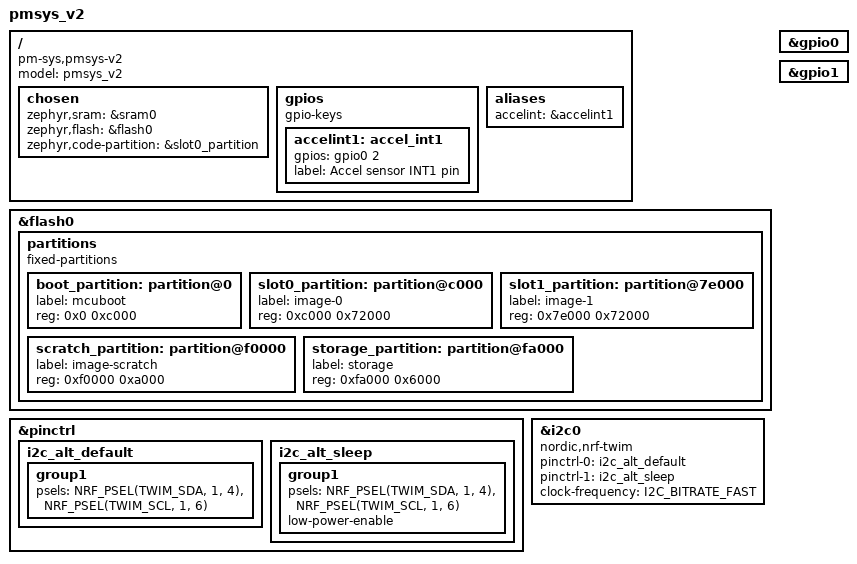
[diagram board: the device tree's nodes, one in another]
// Copyright (c) 2024 Nordic Semiconductor ASA
// SPDX-License-Identifier: Apache-2.0

/dts-v1/;
#include <nordic/nrf52840_qiaa.dtsi>

/ {
	model = "pmsys_v2";
	compatible = "pm-sys,pmsys-v2";

	chosen {
		zephyr,sram = &sram0;
		zephyr,flash = &flash0;
		zephyr,code-partition = &slot0_partition;
	};

	gpios {
		compatible = "gpio-keys";
		accelint1: accel_int1 {
			gpios = <&gpio0 2 (GPIO_PULL_DOWN | GPIO_ACTIVE_HIGH)>;
			label = "Accel sensor INT1 pin";
		};
	};

	aliases {
		accelint = &accelint1;
	};

};

&flash0 {
	partitions {
		compatible = "fixed-partitions";
		#address-cells = <1>;
		#size-cells = <1>;

		boot_partition: partition@0 {
			label = "mcuboot";
			reg = <0x0 0xc000>;
		};
		slot0_partition: partition@c000 {
			label = "image-0";
			reg = <0xc000 0x72000>;
		};
		slot1_partition: partition@7e000 {
			label = "image-1";
			reg = <0x7e000 0x72000>;
		};
		scratch_partition: partition@f0000 {
			label = "image-scratch";
			reg = <0xf0000 0xa000>;
		};
		storage_partition: partition@fa000 {
			label = "storage";
			reg = <0xfa000 0x6000>;
		};
	};
};

&gpio0 {
	status = "okay";
};

&gpio1 {
	status = "okay";
};

&pinctrl {

    i2c_alt_default: i2c_alt_default {
        group1 {
            psels = <NRF_PSEL(TWIM_SDA, 1, 4)>,
                	<NRF_PSEL(TWIM_SCL, 1, 6)>;
        };
    };

    i2c_alt_sleep: i2c_alt_sleep {
        group1 {
            psels = <NRF_PSEL(TWIM_SDA, 1, 4)>,
                	<NRF_PSEL(TWIM_SCL, 1, 6)>;
			low-power-enable;
        };
    };

};

i2c0_inst: &i2c0 {
    compatible = "nordic,nrf-twim";
    status = "okay";
    pinctrl-0 = <&i2c_alt_default>;
	pinctrl-1 = <&i2c_alt_sleep>;
	pinctrl-names = "default", "sleep";
    clock-frequency = < I2C_BITRATE_FAST >;
};





